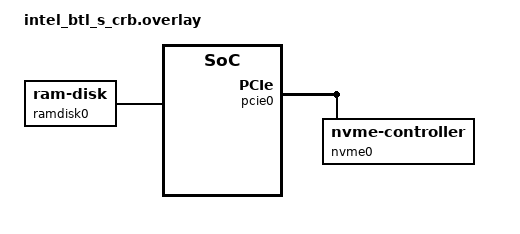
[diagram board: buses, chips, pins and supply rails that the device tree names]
/*
 * Copyright (c) 2025 Intel Corporation
 *
 * SPDX-License-Identifier: Apache-2.0
 */

/ {
	pcie0 {
		nvme0: nvme0 {
			compatible = "nvme-controller";

			vendor-id = <0x1B36>; /* Subjected to change base on Hardware used */
			device-id = <0x0010>; /* Subjected to change base on Hardware used */

			status = "okay";
		};
	};

	ramdisk0 {
		compatible = "zephyr,ram-disk";
		disk-name = "RAM";
		sector-size = <512>;
		sector-count = <192>;
	};
};
